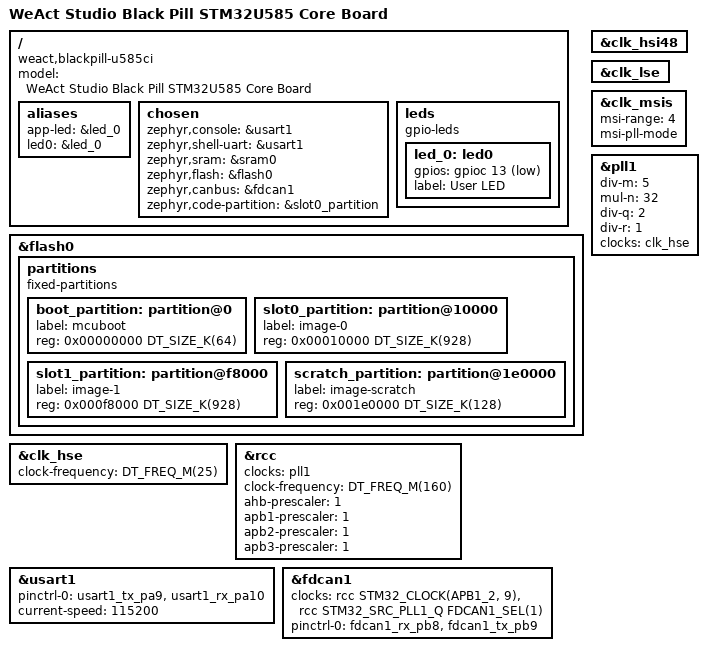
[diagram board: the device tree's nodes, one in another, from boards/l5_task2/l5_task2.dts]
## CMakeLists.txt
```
cmake_minimum_required(VERSION 3.20.0)

list(APPEND BOARD_ROOT ${CMAKE_CURRENT_SOURCE_DIR})
find_package(Zephyr REQUIRED)
project(my_zephyr_app)

target_sources(app PRIVATE src/main.cpp)
add_subdirectory(drivers/custom_driver)
```

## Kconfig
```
menuconfig LED_SUBSYSTEM
    bool "LED Subsystem"
    default y

if LED_SUBSYSTEM

choice 
    prompt "LED blink sleep time"
    default LED_SLEEP_1000

config LED_SLEEP_500
    bool ".5s (fast)"

config LED_SLEEP_1000
    bool "1s (medium)"

config LED_SLEEP_2000
    bool "2s (slow)"

endchoice

config LED_BLINK_SLEEPTIME
    int 
    default 500  if LED_SLEEP_500
    default 1000 if LED_SLEEP_1000
    default 2000 if LED_SLEEP_2000
    default 0

menuconfig ADVANCED_LED_SETTINGS
    bool "Advanced LED Settings"
    default n

if ADVANCED_LED_SETTINGS
config LED_BRIGHTNESS
    int "LED Brightness (0-100)"
    default 100
    range 0 100

config LED_FADE_DURATION
    int "LED Fade Duration (ms)"
    default 500
    range 0 5000

menu "Expert Settings"

config LED_DEBUGGING
    bool "Enable LED Debugging"
    default n

config LED_CUSTOM_PATTERN
    bool "Custom Blink Pattern"
    default n
    
endmenu

endif    

endif

config APP_HEARTBEAT_PERIOD_MS
    int "LED Blink Speed"
    default 500
    range 100 2000

source "Kconfig.zephyr"
rsource "drivers/custom_driver/Kconfig"
```

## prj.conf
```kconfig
CONFIG_GPIO=y
CONFIG_LOG=y
CONFIG_LED_SLEEP_500=y
CONFIG_SENSOR=y
CONFIG_SHELL=y
```

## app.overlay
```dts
/ {

    custom_sensor0: custom_sensor {
        compatible = "custom,driver";
        led-gpios = <&gpioc 13 GPIO_ACTIVE_LOW>;
        status = "okay";
    };
};
```

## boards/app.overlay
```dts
/ {
    aliases{
        app-led=&led_0;
    };
};
```

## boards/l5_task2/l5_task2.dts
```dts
/dts-v1/;
#include <st/u5/stm32u585Xi.dtsi>
#include <st/u5/stm32u585ciux-pinctrl.dtsi>
#include <zephyr/dt-bindings/input/input-event-codes.h>

/ {
	model = "WeAct Studio Black Pill STM32U585 Core Board";
	compatible = "weact,blackpill-u585ci";

	aliases {
        app-led=&led_0;
		led0 = &led_0;
    };

    chosen {
		zephyr,console = &usart1;
		zephyr,shell-uart = &usart1;
		zephyr,sram = &sram0;
		zephyr,flash = &flash0;
		zephyr,canbus = &fdcan1;
		zephyr,code-partition = &slot0_partition;
    }; 

	leds {
		compatible = "gpio-leds";

		led_0: led0 {
			gpios = <&gpioc 13 GPIO_ACTIVE_LOW>;
			label = "User LED";
		};
	};   
};

&flash0 {
	partitions {
		compatible = "fixed-partitions";
		#address-cells = <1>;
		#size-cells = <1>;

		boot_partition: partition@0 {
			label = "mcuboot";
			reg = <0x00000000 DT_SIZE_K(64)>;
		};

		slot0_partition: partition@10000 {
			label = "image-0";
			reg = <0x00010000 DT_SIZE_K(928)>;
		};

		slot1_partition: partition@f8000 {
			label = "image-1";
			reg = <0x000f8000 DT_SIZE_K(928)>;
		};

		scratch_partition: partition@1e0000 {
			label = "image-scratch";
			reg = <0x001e0000 DT_SIZE_K(128)>;
		};
	};
};

&clk_hsi48 {
	status = "okay";
};

&clk_lse {
	status = "okay";
};

&clk_hse {
	clock-frequency = <DT_FREQ_M(25)>;
	status = "okay";
};

&clk_msis {
	status = "okay";
	msi-range = <4>;
	msi-pll-mode;
};

&pll1 {
	div-m = <5>;
	mul-n = <32>;
	div-q = <2>;
	div-r = <1>;
	clocks = <&clk_hse>;
	status = "okay";
};


&rcc {
	clocks = <&pll1>;
	clock-frequency = <DT_FREQ_M(160)>;
	ahb-prescaler = <1>;
	apb1-prescaler = <1>;
	apb2-prescaler = <1>;
	apb3-prescaler = <1>;
};

&usart1 {
	pinctrl-0 = <&usart1_tx_pa9 &usart1_rx_pa10>;
	pinctrl-names = "default";
	current-speed = <115200>;
	status = "okay";
};

&fdcan1 {
	clocks = <&rcc STM32_CLOCK(APB1_2, 9)>,
		 <&rcc STM32_SRC_PLL1_Q FDCAN1_SEL(1)>;
	pinctrl-0 = <&fdcan1_rx_pb8 &fdcan1_tx_pb9>;
	pinctrl-names = "default";
	status = "okay";
};
```

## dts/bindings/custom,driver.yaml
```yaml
description: Custom Driver binding for Blackpill boards
compatible: "custom,driver"
include: base.yaml

properties:
  led-gpios:
    description: GPIO pin for the LED
    type: phandle-array
    required: true
```

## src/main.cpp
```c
#include <zephyr/drivers/gpio.h>
#include <zephyr/drivers/sensor.h>
#include <zephyr/kernel.h>
#include <zephyr/logging/log.h>
#include <zephyr/device.h>

#include "include/custom_driver.h"

//#define SLEEP_TIME_MS 1000

/* The devicetree node identifier for the "led0" alias. */
//#define LED_NODE DT_ALIAS(led0)
//#define LED_NODE DT_ALIAS(customled)

//static const struct gpio_dt_spec led = GPIO_DT_SPEC_GET(LED_NODE, gpios);
//LOG_MODULE_REGISTER(main, LOG_LEVEL_INF);

#define CUSTOM_SENSOR_NODE  DT_NODELABEL(custom_sensor0)

bool invert = false;
int cycles = 0;

int main(void)
{
    //bool led_state = true;
    //if (!gpio_is_ready_dt(&led)) return 0;
    //if (gpio_pin_configure_dt(&led, GPIO_OUTPUT_ACTIVE) < 0) return 0;

    const struct device *dev = DEVICE_DT_GET(CUSTOM_SENSOR_NODE);

    struct sensor_value val;
    if(!device_is_ready(dev)){
        return 0;
    }

    while (1) {
        /*if (gpio_pin_toggle_dt(&led) < 0) return 0;

        led_state = !led_state;
        LOG_INF("LED state: %s", led_state ? "ON" : "OFF");
        //k_msleep(SLEEP_TIME_MS);
        //k_msleep(CONFIG_LED_BLINK_SLEEPTIME);
        k_msleep(CONFIG_APP_HEARTBEAT_PERIOD_MS);*/

        int ret = sensor_sample_fetch(dev);
        k_msleep(CONFIG_APP_HEARTBEAT_PERIOD_MS);
        
        ret = sensor_channel_get(dev, SENSOR_CHAN_ALL, &val);
        k_msleep(CONFIG_APP_HEARTBEAT_PERIOD_MS);

        if (++cycles >= 5) {
            cycles = 0;
            invert = !invert;
            custom_driver_set_invert(dev, invert);
        }
    }
    return 0;
}
```
